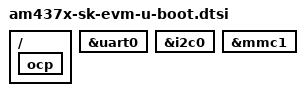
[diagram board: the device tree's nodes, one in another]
// SPDX-License-Identifier: GPL-2.0+
/*
 * Copyright (C) 2018 Texas Instruments Incorporated - https://www.ti.com/
 */

#include "am4372-u-boot.dtsi"

/{
	ocp {
		bootph-pre-ram;
	};
};

&uart0 {
	bootph-pre-ram;
};

&i2c0 {
	bootph-pre-ram;
};

&mmc1 {
	bootph-pre-ram;
};
